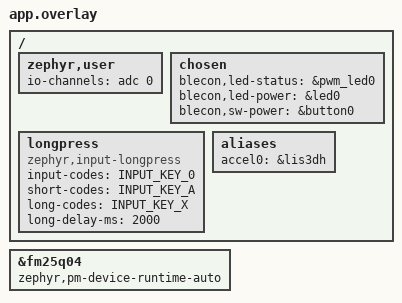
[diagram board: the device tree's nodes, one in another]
/*
 * Copyright (c) Blecon Ltd
 * SPDX-License-Identifier: Apache-2.0
 */

/ {
    zephyr,user {
		io-channels = <&adc 0>;
	};
	chosen {
		blecon,led-status = &pwm_led0;
		blecon,led-power = &led0;
		blecon,sw-power = &button0;
	};
	longpress {
        compatible = "zephyr,input-longpress";
        input-codes = <INPUT_KEY_0>;
		short-codes = <INPUT_KEY_A>;
		long-codes = <INPUT_KEY_X>;
        long-delay-ms = <2000>;
	};
	aliases {
		accel0 = &lis3dh;
	};
};

&fm25q04 {
	zephyr,pm-device-runtime-auto;
};
